VERSION ""

NS_ :

BS_:

BU_: XXX

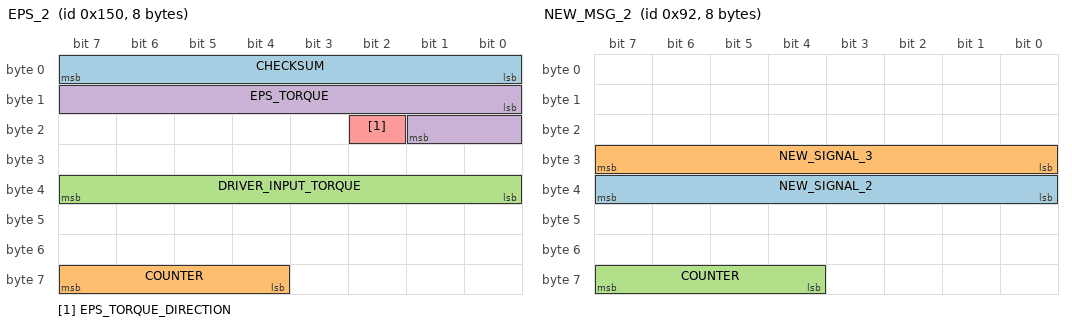
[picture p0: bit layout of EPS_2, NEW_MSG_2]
BO_ 336 EPS_2: 8 XXX
 SG_ CHECKSUM : 7|8@0+ (1,0) [0|255] "" XXX
 SG_ COUNTER : 63|4@0+ (1,0) [0|15] "" XXX
 SG_ DRIVER_INPUT_TORQUE : 32|8@1+ (1,0) [0|255] "" XXX
 SG_ EPS_TORQUE : 8|10@1- (1,0) [0|255] "" XXX
 SG_ EPS_TORQUE_DIRECTION : 18|1@0+ (1,0) [0|1] "direction" XXX

BO_ 146 NEW_MSG_2: 8 XXX
 SG_ NEW_SIGNAL_2 : 39|8@0+ (1,0) [0|255] "" XXX
 SG_ NEW_SIGNAL_3 : 31|8@0+ (1,0) [0|255] "" XXX
 SG_ COUNTER : 63|4@0+ (1,0) [0|15] "" XXX

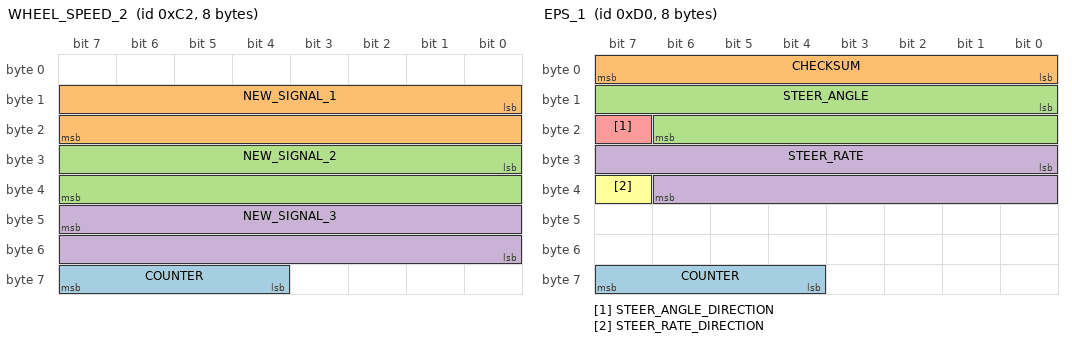
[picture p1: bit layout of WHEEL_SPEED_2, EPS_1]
BO_ 194 WHEEL_SPEED_2: 8 XXX
 SG_ COUNTER : 63|4@0+ (1,0) [0|15] "" XXX
 SG_ NEW_SIGNAL_1 : 8|16@1+ (1,0) [0|65535] "" XXX
 SG_ NEW_SIGNAL_2 : 24|16@1+ (1,0) [0|65535] "" XXX
 SG_ NEW_SIGNAL_3 : 47|16@0+ (1,0) [0|65535] "" XXX

BO_ 208 EPS_1: 8 XXX
 SG_ COUNTER : 63|4@0+ (1,0) [0|15] "" XXX
 SG_ CHECKSUM : 0|8@1+ (1,0) [0|15] "" XXX
 SG_ STEER_ANGLE : 8|15@1+ (0.0225,0) [0|65535] "" XXX
 SG_ STEER_RATE : 24|15@1+ (0.0225,0) [0|65535] "" XXX
 SG_ STEER_ANGLE_DIRECTION : 23|1@0+ (1,0) [0|1] "direction" XXX
 SG_ STEER_RATE_DIRECTION : 39|1@0+ (1,0) [0|1] "direction" XXX

BO_ 144 NEW_MSG_5: 8 XXX
 SG_ NEW_SIGNAL_1 : 32|12@1+ (1,0) [0|4095] "" XXX

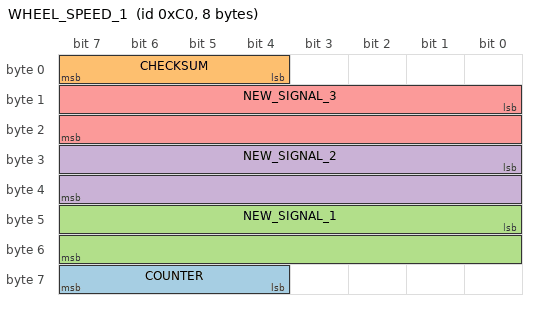
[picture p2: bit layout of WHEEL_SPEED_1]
BO_ 192 WHEEL_SPEED_1: 8 XXX
 SG_ COUNTER : 63|4@0+ (1,0) [0|15] "" XXX
 SG_ CHECKSUM : 7|4@0+ (1,0) [0|15] "" XXX
 SG_ NEW_SIGNAL_1 : 40|16@1+ (1,0) [0|65535] "" XXX
 SG_ NEW_SIGNAL_2 : 24|16@1+ (1,0) [0|65535] "" XXX
 SG_ NEW_SIGNAL_3 : 8|16@1+ (1,0) [0|65535] "" XXX

CM_ SG_ 336 EPS_TORQUE_DIRECTION "0=right, 1=left";
CM_ SG_ 208 STEER_ANGLE_DIRECTION "0=right, 1=left";
CM_ SG_ 208 STEER_RATE_DIRECTION "0=right, 1=left";
